VERSION ""

NS_ :

BS_:

BU_: VCU ACU
VAL_TABLE_ Agv_St 2 "ON" 1 "STOP" 0 "Inivd" ;

BO_ 3221225472 VECTOR__INDEPENDENT_SIG_MSG: 0 Vector__XXX
 SG_ VCU1_RemoteValid : 0|1@1+ (1,0) [0|1] "" Vector__XXX

BO_ 801 Agv: 8 Vector__XXX
 SG_ Agv_Message_St : 0|2@1+ (1,0) [0|0] "" Vector__XXX

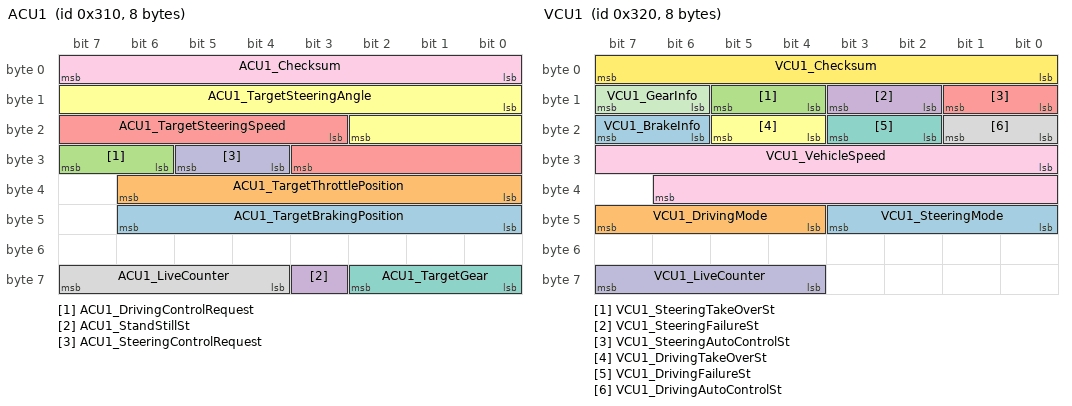
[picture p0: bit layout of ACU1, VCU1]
BO_ 784 ACU1: 8 ACU
 SG_ ACU1_TargetBrakingPosition : 40|7@1+ (1,0) [0|100] "%" Vector__XXX
 SG_ ACU1_TargetThrottlePosition : 32|7@1+ (1,0) [0|100] "%" Vector__XXX
 SG_ ACU1_DrivingControlRequest : 30|2@1+ (1,0) [0|3] "" Vector__XXX
 SG_ ACU1_StandStillSt : 59|1@1+ (1,0) [0|1] "" Vector__XXX
 SG_ ACU1_TargetSteeringSpeed : 19|9@1+ (1,0) [0|500] "deg/s" Vector__XXX
 SG_ ACU1_TargetSteeringAngle : 8|11@1+ (1,-600) [-600|600] "deg" Vector__XXX
 SG_ ACU1_TargetGear : 56|3@1+ (1,0) [0|7] "" Vector__XXX
 SG_ ACU1_LiveCounter : 60|4@1+ (1,0) [0|15] "" Vector__XXX
 SG_ ACU1_Checksum : 0|8@1+ (1,0) [0|255] "" Vector__XXX
 SG_ ACU1_SteeringControlRequest : 28|2@1+ (1,0) [0|3] "" Vector__XXX

BO_ 800 VCU1: 8 VCU
 SG_ VCU1_SteeringMode : 40|4@1+ (1,0) [0|15] "" Vector__XXX
 SG_ VCU1_DrivingMode : 44|4@1+ (1,0) [0|15] "" Vector__XXX
 SG_ VCU1_SteeringTakeOverSt : 12|2@1+ (1,0) [0|3] "" Vector__XXX
 SG_ VCU1_SteeringFailureSt : 10|2@1+ (1,0) [0|3] "" Vector__XXX
 SG_ VCU1_SteeringAutoControlSt : 8|2@1+ (1,0) [0|3] "" Vector__XXX
 SG_ VCU1_DrivingTakeOverSt : 20|2@1+ (1,0) [0|3] "" Vector__XXX
 SG_ VCU1_DrivingFailureSt : 18|2@1+ (1,0) [0|3] "" Vector__XXX
 SG_ VCU1_DrivingAutoControlSt : 16|2@1+ (1,0) [0|3] "" Vector__XXX
 SG_ VCU1_VehicleSpeed : 24|15@1+ (1,0) [0|60] "km/h" Vector__XXX
 SG_ VCU1_LiveCounter : 60|4@1+ (1,0) [0|15] "" Vector__XXX
 SG_ VCU1_GearInfo : 14|2@1+ (1,0) [0|3] "" Vector__XXX
 SG_ VCU1_Checksum : 0|8@1+ (1,0) [0|255] "" Vector__XXX
 SG_ VCU1_BrakeInfo : 22|2@1+ (1,0) [0|3] "" Vector__XXX

CM_ BO_ 3221225472 "This is a message for not used signals, created by Vector CANdb++ DBC OLE DB Provider.";
CM_ SG_ 3221225472 VCU1_RemoteValid "Ò£¿ØÆ÷ÓÐÐ§×´Ì¬";
BA_DEF_ BO_  "GenMsgType" ENUM  "N","T","R";
BA_DEF_  "VersionYear" INT 0 2099;
BA_DEF_  "VersionMonth" INT 0 12;
BA_DEF_  "VersionDay" INT 0 31;
BA_DEF_  "Baudrate" INT 0 1000000;
BA_DEF_ BO_  "GenMsgCycleTime" INT 0 10000;
BA_DEF_  "DBName" STRING ;
BA_DEF_  "BusType" STRING ;
BA_DEF_DEF_  "GenMsgType" "N";
BA_DEF_DEF_  "VersionYear" 2020;
BA_DEF_DEF_  "VersionMonth" 1;
BA_DEF_DEF_  "VersionDay" 1;
BA_DEF_DEF_  "Baudrate" 500000;
BA_DEF_DEF_  "GenMsgCycleTime" 10;
BA_DEF_DEF_  "DBName" "VENUS";
BA_DEF_DEF_  "BusType" "CAN";
BA_ "DBName" "EDU";
BA_ "GenMsgCycleTime" BO_ 784 20;
BA_ "GenMsgType" BO_ 784 2;
BA_ "GenMsgType" BO_ 800 1;
VAL_ 3221225472 VCU1_RemoteValid 3 "Reserved" 2 "Active" 1 "Temporary" 0 "Inactive" ;
VAL_ 801 Agv_Message_St 2 "ON" 1 "STOP" 0 "Inivd" ;
VAL_ 784 ACU1_DrivingControlRequest 3 "Reserved" 2 "Reserved" 1 "Request" 0 "No Requet" ;
VAL_ 784 ACU1_StandStillSt 1 "Active" 0 "Inactive" ;
VAL_ 784 ACU1_TargetGear 7 "Reserved" 6 "Reserved" 5 "Reserved" 4 "R" 3 "N" 2 "D" 1 "P" 0 "No Request" ;
VAL_ 784 ACU1_SteeringControlRequest 3 "Reserved" 2 "Reserved" 1 "Request" 0 "No Requet" ;
VAL_ 800 VCU1_SteeringTakeOverSt 3 "Reserved" 2 "Active" 1 "Temporary" 0 "Inactive" ;
VAL_ 800 VCU1_SteeringFailureSt 3 "Reserved" 2 "SAS Fail" 1 "EPS Fail" 0 "No Fail" ;
VAL_ 800 VCU1_SteeringAutoControlSt 3 "Reserved" 2 "Reserved" 1 "Active" 0 "Inactive" ;
VAL_ 800 VCU1_DrivingTakeOverSt 3 "Reserved" 2 "Take Over" 1 "Temporary" 0 "Inactive" ;
VAL_ 800 VCU1_DrivingFailureSt 3 "Reserved" 2 "Motor Fail" 1 "HCU Fail" 0 "No Fail" ;
VAL_ 800 VCU1_DrivingAutoControlSt 3 "Reserved" 2 "Reserved" 1 "Active" 0 "Inactive" ;
VAL_ 800 VCU1_GearInfo 3 "D" 2 "N" 1 "R" 0 "P" ;
VAL_ 800 VCU1_BrakeInfo 3 "Reserved" 2 "Reserved" 1 "Active" 0 "Inactive" ;
